# STM32WB05 register map
File version: 1.0
CPU: CM0+ r0p0, little endian, MPU, no FPU, 2 interrupt priority bits
Registers are 32-bit, read-write, reset 0x0 unless marked. A register's access mark holds for its fields unless they carry their own. Offsets are from the block's base; [hi:lo] are bit positions; {n}, {i} and the like mark numbered series; 'fields as' and 'values as' point back to an identical list.

## TIM16
Base 0x40005000
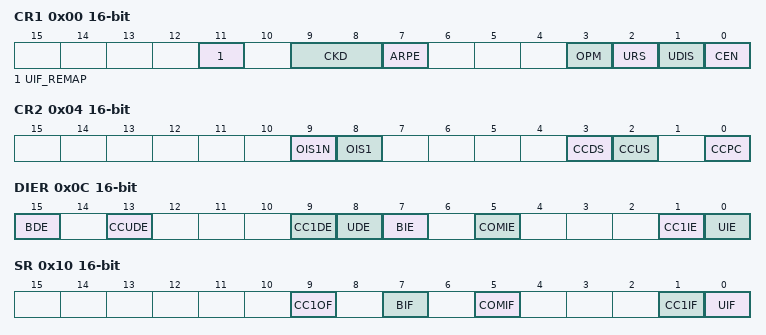
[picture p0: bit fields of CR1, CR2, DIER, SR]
0x00 CR1 16-bit
  [11] UIF_REMAP — UIFREMAP: UIF status bit remapping 0: No remapping. UIF status bit is not copied to TIMx_CNT register bit 31. 1: Remapping enabled. UIF status bit is copied to TIMx_CNT register bit 31.
  [9:8] CKD — CKD[1:0]: Clock division This bit-field indicates the division ratio between the timer clock (CK_INT) frequency and the dead-time and sampling clock (tDTS)used by the dead-time generators and the digital filters (TIx), 00: tDTS=tCK_INT 01: tDTS=2*tCK_INT 10: tDTS=4*tCK_INT 11: Reserved, do not program this value
    0=Div1 (t_DTS = t_CK_INT); 1=Div2 (t_DTS = 2 × t_CK_INT); 2=Div4 (t_DTS = 4 × t_CK_INT)
  [7] ARPE — ARPE: Auto-reload preload enable 0: TIMx_ARR register is not buffered 1: TIMx_ARR register is buffered
    0=Disabled (TIMx_APRR register is not buffered); 1=Enabled (TIMx_APRR register is buffered)
  [3] OPM — OPM: One pulse mode 0: Counter is not stopped at update event. 1: Counter stops counting at the next update event (clearing the bit CEN)
    0=Disabled (Counter is not stopped at update event); 1=Enabled (Counter stops counting at the next update event (clearing the CEN bit))
  [2] URS — URS: Update request source This bit is set and cleared by software to select the UEV event sources. 0: Any of the following events generate an update interrupt or DMA request if enabled. These events can be: - Counter overflow/underflow - Setting the UG bit - Update generation through the slave mode controller 1: Only counter overflow/underflow generates an update interrupt or DMA request if enabled.
    0=AnyEvent (Any of counter overflow/underflow, setting UG, or update through slave mode, generates an update interrupt or DMA request); 1=CounterOnly (Only counter overflow/underflow generates an update interrupt or DMA request)
  [1] UDIS — UDIS: Update disable This bit is set and cleared by software to enable/disable UEV event generation. 0: UEV enabled. The Update (UEV) event is generated by one of the following events: - Counter overflow/underflow - Setting the UG bit - Update generation through the slave mode controller Buffered registers are then loaded with their preload values. 1: UEV disabled. The Update event is not generated, shadow registers keep their value (ARR, PSC, CCRx). However the counter and the prescaler are reinitialized if the UG bit is set or if a hardware reset is received from the slave mode controller.
    0=Enabled (Update event enabled); 1=Disabled (Update event disabled)
  [0] CEN — CEN: Counter enable 0: Counter disabled 1: Counter enabled Note: External clock and gated mode can work only if the CEN bit has been previously set by software. However trigger mode can set the CEN bit automatically by hardware.
    0=Disabled (Counter disabled); 1=Enabled (Counter enabled)
0x04 CR2 16-bit
  [n+8] OIS{n}N (n=1..1) — Output Idle state (OC{n}N output)
    0=Reset (OCxN=0 after a dead-time when MOE=0); 1=Set (OCxN=1 after a dead-time when MOE=0)
  [n+7] OIS{n} (n=1..1) — Output Idle state (OC{n} output)
    0=Reset (OCx=0 (after a dead-time if OCx(N) is implemented) when MOE=0); 1=Set (OCx=1 (after a dead-time if OCx(N) is implemented) when MOE=0)
  [3] CCDS — CCDS: Capture/compare DMA selection 0: CCx DMA request sent when CCx event occurs 1: CCx DMA requests sent when update event occurs
    0=OnCompare (CCx DMA request sent when CCx event occurs); 1=OnUpdate (CCx DMA request sent when update event occurs)
  [2] CCUS — CCUS: Capture/compare control update selection 0: When capture/compare control bits are preloaded (CCPC=1), they are updated by setting the COMG bit only. 1: When capture/compare control bits are preloaded (CCPC=1), they are updated by setting the COMG bit or when an rising edge occurs on TRGI. Note: This bit acts only on channels that have a complementary output.
    0=Sw (When capture/compare control bits are preloaded (CCPC=1), they are updated by setting the COMG bit only); 1=SwOrEdge (When capture/compare control bits are preloaded (CCPC=1), they are updated by setting the COMG bit or when an rising edge occurs on TRGI)
  [0] CCPC — CCPC: Capture/compare preloaded control 0: CCxE, CCxNE and OCxM bits are not preloaded 1: CCxE, CCxNE and OCxM bits are preloaded, after having been written, they are updated only when COM bit is set. Note: This bit acts only on channels that have a complementary output.
    0=NotPreloaded (CCxE, CCxNE and OCxM bits are not preloaded); 1=Preloaded (CCxE, CCxNE and OCxM bits are preloaded)
0x0C DIER 16-bit
  [15] BDE — BDE: Break DMA request Enable. Not used in Blue51. Not available in IUM 0: Break DMA request disabled. 1: Break DMA request enabled.
  [9] CC{x}DE (x=1,U; step 4) — Capture/Compare {x} DMA request enable
    0=Disabled (CCx DMA request disabled); 1=Enabled (CCx DMA request enabled)
  [8] UDE — UDE: Update DMA request enable 0: Update DMA request disabled 1: Update DMA request enabled
    0=Disabled (Update DMA request disabled); 1=Enabled (Update DMA request enabled)
  [7] BIE — BIE: Break interrupt enable 0: Break interrupt disabled 1: Break interrupt enabled
    0=Disabled (Break interrupt disabled); 1=Enabled (Break interrupt enabled)
  [5] COMIE — COMIE: COM interrupt enable 0: COM interrupt disabled 1: COM interrupt enabled
    0=Disabled (COM interrupt disabled); 1=Enabled (COM interrupt enabled)
  [n] CC{n}IE (n=1..1) — Capture/Compare {n} interrupt enable
    0=Disabled (CCx interrupt disabled); 1=Enabled (CCx interrupt enabled)
  [0] UIE — UIE: Update interrupt enable 0: Update interrupt disabled 1: Update interrupt enabled
    0=Disabled (Update interrupt disabled); 1=Enabled (Update interrupt enabled)
0x10 SR 16-bit
  [n+8] CC{n}OF (n=1..1) write-0-clears — Capture/Compare {n} overcapture flag
    on read: 0=No overcapture has been detected; 1=Overcapture (The counter value has been captured in TIMx_CCRx register while CCxIF flag was already set) | on write: 0=Clear flag
  [7] BIF write-0-clears — BIF: Break interrupt flag This flag is set by hardware as soon as the break input goes active. It can be cleared by software if the break input is not active. 0: No break event occurred 1: An active level has been detected on the break input
    on read: 0=NoTrigger (No break event occurred); 1=Trigger (An active level has been detected on the break input. An interrupt is generated if BIE=1 in the TIMx_DIER register) | on write: 0=Clear flag
  [5] COMIF write-0-clears — COMIF: COM interrupt flag This flag is set by hardware on a COM event (once the capture/compare control bits CCxE, CCxNE, OCxMhave been updated). It is cleared by software. 0: No COM event occurred 1: COM interrupt pending
    on read: 0=No COM event occurred; 1=COM (COM interrupt pending) | on write: 0=Clear flag
  [n] CC{n}IF (n=1..1) write-0-clears — Capture/compare {n} interrupt flag
    on read: 0=NoMatch (No campture/compare has been detected); 1=Match (If CC1 is an output: The content of the counter TIMx_CNT matches the content of the TIMx_CCR1 register. If CC1 is an input: The counter value has been captured in TIMx_CCR1 register.) | on write: 0=Clear flag
  [0] UIF write-0-clears — UIF: Update interrupt flag This bit is set by hardware on an update event. It is cleared by software. 0: No update occurred. 1: Update interrupt pending. This bit is set by hardware when the registers are updated: At overflow regarding the repetition counter value (update if repetition counter = 0) and if the UDIS=0 in the TIMx_CR1 register. When CNT is reinitialized by software using the UG bit in TIMx_EGR register, if URS=0 and UDIS=0 in the TIMx_CR1 register.
    on read: 0=NoUpdateOccurred; 1=UpdatePending (Update interrupt pending) | on write: 0=Clear flag
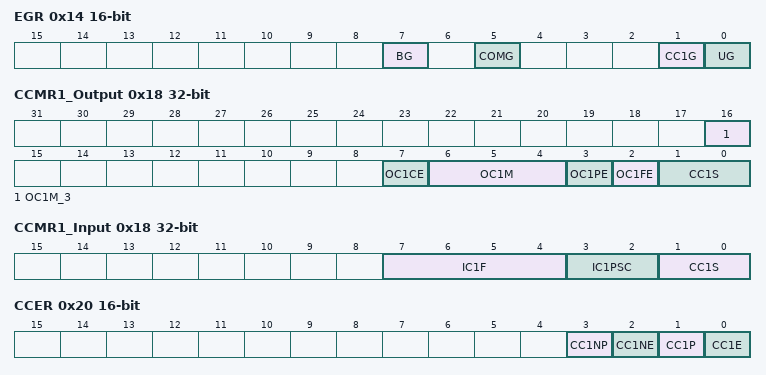
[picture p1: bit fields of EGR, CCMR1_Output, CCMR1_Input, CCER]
0x14 EGR 16-bit
  [7] BG wo — BG: Break generation This bit is set by software in order to generate an event, it is automatically cleared by hardware. 0: No action. 1: A break event is generated. MOE bit is cleared and BIF flag is set. Related interrupt or DMA transfer can occur if enabled.
    1=Trigger (A break event is generated. MOE bit is cleared and BIF flag is set. Related interrupt or DMA transfer can occur if enabled)
  [5] COMG wo — COMG: Capture/Compare control update generation This bit can be set by software, it is automatically cleared by hardware. 0: No action 1: When the CCPC bit is set, it is possible to update the CCxE, CCxNE and OCxM bits Note: This bit acts only on channels that have a complementary output.
    1=Trigger (When CCPC bit is set, it allows CCxE, CCxNE and OCxM bits to be updated)
  [n] CC{n}G (n=1..1) wo — Capture/compare {n} generation
    1=Trigger (If CC1 is an output: CC1IF flag is set, Corresponding interrupt or DMA request is sent if enabled. If CC1 is an input: The current value of the counter is captured in TIMx_CCR1 register.)
  [0] UG wo — UG: Update generation This bit can be set by software, it is automatically cleared by hardware. 0: No action. 1: Reinitialize the counter and generates an update of the registers. Note that the prescaler counter is cleared too (anyway the prescaler ratio is not affected).
    1=Update (Re-initializes the timer counter and generates an update of the registers.)
0x18 CCMR1_Output — CCMR1 register
  [n+15] OC{n}M_3 (n=1..1) — Output compare {n} mode, bit 3
  [n+6] OC{n}CE (n=1..1) — Output compare {n} clear enable
  [n+5:n+3] OC{n}M (n=1..1) — Output compare {n} mode
    0=Frozen (The comparison between the output compare register TIMx_CCRy and the counter TIMx_CNT has no effect on the outputs); 1=ActiveOnMatch (Set channel to active level on match. OCyREF signal is forced high when the counter matches the capture/compare register); 2=InactiveOnMatch (Set channel to inactive level on match. OCyREF signal is forced low when the counter matches the capture/compare register); 3=Toggle (OCyREF toggles when TIMx_CNT=TIMx_CCRy); 4=ForceInactive (OCyREF is forced low); 5=ForceActive (OCyREF is forced high); 6=PwmMode1 (In upcounting, channel is active as long as TIMx_CNT<TIMx_CCRy else inactive. In downcounting, channel is inactive as long as TIMx_CNT>TIMx_CCRy else active); 7=PwmMode2 (Inversely to PwmMode1)
  [n+2] OC{n}PE (n=1..1) — Output compare {n} preload enable
    0=Disabled (Preload register on CCRx disabled. New values written to CCRx are taken into account immediately); 1=Enabled (Preload register on CCRx enabled. Preload value is loaded into active register on each update event)
  [n+1] OC{n}FE (n=1..1) — Output compare {n} fast enable
    0=Disabled (Fast output disabled); 1=Enabled (Fast output enabled)
  [n:n-1] CC{n}S (n=1..1) — Capture/Compare {n} selection
    0=Output (CCx channel is configured as output)
0x18 CCMR1_Input (reset mask 0xF) (alternate view of CCMR1)
  [n+6:n+3] IC{n}F (n=1..1) — Input capture {n} filter
    0=No filter, sampling is done at fDTS; 1=FCK_INT_N2 (fSAMPLING=fCK_INT, N=2); 2=FCK_INT_N4 (fSAMPLING=fCK_INT, N=4); 3=FCK_INT_N8 (fSAMPLING=fCK_INT, N=8); 4=FDTS_Div2_N6 (fSAMPLING=fDTS/2, N=6); 5=FDTS_Div2_N8 (fSAMPLING=fDTS/2, N=8); 6=FDTS_Div4_N6 (fSAMPLING=fDTS/4, N=6); 7=FDTS_Div4_N8 (fSAMPLING=fDTS/4, N=8); 8=FDTS_Div8_N6 (fSAMPLING=fDTS/8, N=6); 9=FDTS_Div8_N8 (fSAMPLING=fDTS/8, N=8); 10=FDTS_Div16_N5 (fSAMPLING=fDTS/16, N=5); 11=FDTS_Div16_N6 (fSAMPLING=fDTS/16, N=6); 12=FDTS_Div16_N8 (fSAMPLING=fDTS/16, N=8); 13=FDTS_Div32_N5 (fSAMPLING=fDTS/32, N=5); 14=FDTS_Div32_N6 (fSAMPLING=fDTS/32, N=6); 15=FDTS_Div32_N8 (fSAMPLING=fDTS/32, N=8)
  [n+2:n+1] IC{n}PSC (n=1..1) — Input capture {n} prescaler
    0=No prescaler, capture is done each time an edge is detected on the capture input; 1=TwoEvents (Capture is done once every 2 events); 2=FourEvents (Capture is done once every 4 events); 3=EightEvents (Capture is done once every 8 events)
  [1:0] CC1S — CC1S: Capture/Compare 1 Selection This bit-field defines the direction of the channel (input/output) as well as the used input. 00: CC1 channel is configured as output 01: CC1 channel is configured as input, IC1 is mapped on TI1 1x: Reserved Note: CC1S bits are writable only when the channel is OFF (CC1E = '0' in TIMx_CCER).
    1=TI1 (CC1 channel is configured as input, IC1 is mapped on TI1)
0x20 CCER 16-bit
  [n+2] CC{n}NP (n=1..1) — Capture/Compare {n} output Polarity
    0=ActiveHigh (OCxN active high); 1=ActiveLow (OCxN active low)
  [n+1] CC{n}NE (n=1..1) — Capture/Compare {n} complementary output enable
    0=Disabled (Complementary output disabled); 1=Enabled (Complementary output enabled)
  [n] CC{n}P (n=1..1) — Capture/Compare {n} output Polarity
    0=RisingEdge (Noninverted/rising edge); 1=FallingEdge (Inverted/falling edge)
  [n-1] CC{n}E (n=1..1) — Capture/Compare {n} output enable
    0=Disabled (Capture disabled); 1=Enabled (Capture enabled)
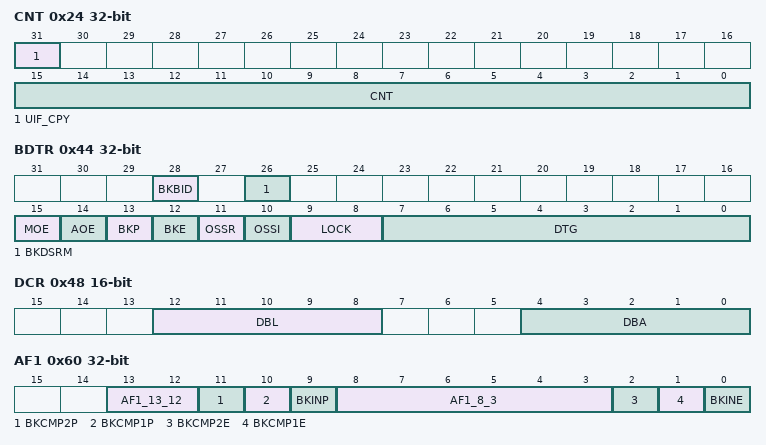
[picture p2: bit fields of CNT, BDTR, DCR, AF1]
0x24 CNT
  [31] UIF_CPY ro — UIFCPY: UIF Copy This bit is a read-only copy of the UIF bit of the TIMx_ISR register. If the UIFREMAP bit in TIMx_CR1 is reset, bit 31 is reserved and read as 0.
  [15:0] CNT — CNT[15:0]: Counter value
0x24 CNT16 16-bit (alternate view of CNT) — 16-bit counter register
  [15:0] CNT — counter value
0x28 PSC 16-bit
  [15:0] PSC — PSC[15:0]: Prescaler value The counter clock frequency (CK_CNT) is equal to fCK_PSC / (PSC[15:0] + 1). PSC contains the value to be loaded in the active prescaler register at each update event (including when the counter is cleared through UG bit of TIMx_EGR register or through trigger controller when configured in 'reset mode').
0x2C ARR 16-bit reset 0xFFFF
  [15:0] ARR — ARR[15:0]: Prescaler value ARR is the value to be loaded in the actual auto-reload register. Refer to the Section 22.3.1: Time-base unit on page 418 for more details about ARR update and behavior. The counter is blocked while the auto-reload value is null.
0x30 RCR 16-bit
  [7:0] REP — REP[7:0]: Repetition counter value These bits allow the user to set-up the update rate of the compare registers (i.e. periodic transfers from preload to active registers) when preload registers are enable, as well as the update interrupt generation rate, if this interrupt is enable. Each time the REP_CNT related downcounter reaches zero, an update event is generated and it restarts counting from REP value. As REP_CNT is reloaded with REP value only at the repetition update event U_RC, any write to the TIMx_RCR register is not taken in account until the next repetition update event. It means in PWM mode (REP+1) corresponds to the number of PWM periods in edge-aligned mode.
{0x32+2i} CCR{i} (i=1..1) 16-bit — capture/compare register
  [15:0] CCR — CCR1[15:0]: Capture/Compare 1 value If channel CC1 is configured as output: CCR1 is the value to be loaded in the actual capture/compare 1 register (preload value). It is loaded permanently if the preload feature is not selected in the TIMx_CCMR1 register (bit OC1PE). Else the preload value is copied in the active capture/compare 1 register when an update event occurs. The active capture/compare register contains the value to be compared to the counter TIMx_CNT and signaled on OC1 output. If channel CC1 is configured as input: CCR1 is the counter value transferred by the last input capture 1 event (IC1).
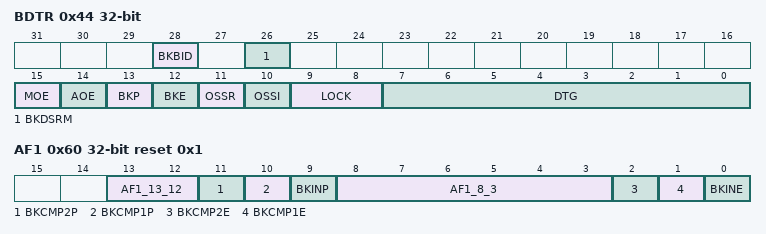
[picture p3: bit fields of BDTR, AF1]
0x44 BDTR
  [28] BKBID — BKBID: Break Bidirectional 0: Break input BRK in input mode 1: Break input BRK in bidirectional mode In the bidirectional mode (BKBID bit set to 1), the break input is configured both in input mode and in open drain output mode. Any active break event asserts a low logic level on the Break input to indicate an internal break event to external devices. Note: This bit cannot be modified as long as LOCK level 1 has been programmed (LOCK bits in TIMx_BDTR register). Note: Any write operation to this bit takes a delay of 1 APB clock cycle to become effective.
  [26] BKDSRM — BKDSRM: Break Disarm 0: Break input BRK is armed 1: Break input BRK is disarmed This bit is cleared by hardware when no break source is active. The BKDSRM bit must be set by software to release the bidirectional output control (opendrain output in Hi-Z state) and then be polled it until it is reset by hardware, indicating that the fault condition has disappeared. Note: Any write operation to this bit takes a delay of 1 APB clock cycle to become effective.
  [15] MOE — MOE: Main output enable This bit is cleared asynchronously by hardware as soon as the break input is active. It is set by software or automatically depending on the AOE bit. It is acting only on the channels which are configured in output. 0: OC and OCN outputs are disabled or forced to idle state depending on the OSSI bit. 1: OC and OCN outputs are enabled if their respective enable bits are set (CCxE, CCxNE in TIMx_CCER register) See OC/OCN enable description for more details (Section 22.4.8: TIM16 capture/compare enable register (TIMx_CCER)).
    0=DisabledIdle (OC/OCN are disabled or forced idle depending on OSSI); 1=Enabled (OC/OCN are enabled if CCxE/CCxNE are set)
  [14] AOE — AOE: Automatic output enable not be active) Note: This bit can not be modified as long as LOCK level 1 has been programmed (LOCK bits in TIMx_BDTR register).
    0=Manual (MOE can be set only by software); 1=Automatic (MOE can be set by software or automatically at the next update event (if none of the break inputs BRK and BRK2 is active))
  [13] BKP — BKP: Break polarity 0: Break input BRK is active low. 1: Break input BRK is active high Note: 1. This bit can not be modified as long as LOCK level 1 has been programmed (LOCK bits in TIMx_BDTR register). Note: 2. Any write operation to this bit takes a delay of 1 APB clock cycle to become effective.
    0=ActiveLow (Break input BRKx is active low); 1=ActiveHigh (Break input BRKx is active high)
  [12] BKE — BKE: Break enable 1; Break inputs (BRK) enabled Note: 1. This bit cannot be modified when LOCK level 1 has been programmed (LOCK bits in TIMx_BDTR register). Note: 2. Any write operation to this bit takes a delay of 1 APB clock cycle to become effective.
    0=Disabled (Break function x disabled); 1=Enabled (Break function x enabled)
  [11] OSSR — OSSR: Off-state selection for Run mode This bit is used when MOE=1 on channels that have a complementary output which are configured as outputs. OSSR is not implemented if no complementary output is implemented in the timer. See OC/OCN enable description for more details (Section 22.4.8: TIM16 capture/compare enable register (TIMx_CCER)). 0: When inactive, OC/OCN outputs are disabled (the timer releases the output control which is taken over by the AFIO logic, which forces a Hi-Z state) 1: When inactive, OC/OCN outputs are enabled with their inactive level as soon as CCxE=1 or CCxNE=1 (the output is still controlled by the timer). Note: This bit can not be modified as soon as the LOCK level 2 has been programmed (LOCK bits in TIMx_BDTR register).
    0=HiZ (When inactive, OC/OCN outputs are disabled); 1=IdleLevel (When inactive, OC/OCN outputs are enabled with their inactive level)
  [10] OSSI — OSSI: Off-state selection for Idle mode This bit is used when MOE=0 on channels configured as outputs. See OC/OCN enable description for more details (Section 22.4.8: TIM16 capture/compare enable register (TIMx_CCER)). 0: When inactive, OC/OCN outputs are disabled (OC/OCN enable output signal=0) 1: When inactive, OC/OCN outputs are forced first with their idle level as soon as CCxE=1 or CCxNE=1. OC/OCN enable output signal=1) Note: This bit can not be modified as soon as the LOCK level 2 has been programmed (LOCK bits in TIMx_BDTR register).
    0=HiZ (When inactive, OC/OCN outputs are disabled); 1=IdleLevel (When inactive, OC/OCN outputs are forced to idle level)
  [9:8] LOCK — LOCK[1:0]: Lock configuration These bits offer a write protection against software errors. 00: LOCK OFF - No bit is write protected 01: LOCK Level 1 = DTG bits in TIMx_BDTR register, OISx and OISxN bits in TIMx_CR2 register, BKE/BKP/AOE/BKBID/BKDSRM bits in TIMx_BDTR register and all used bits in TIMx_AF1 register can no longer be written. 10: LOCK Level 2 = LOCK Level 1 + CC Polarity bits (CCxP/CCxNP bits in TIMx_CCER register, as long as the related channel is configured in output through the CCxS bits) as well as OSSR and OSSI bits can no longer be written. 11: LOCK Level 3 = LOCK Level 2 + CC Control bits (OCxM and OCxPE bits in TIMx_CCMRx registers, as long as the related channel is configured in output through the CCxS bits) can no longer be written. Note: The LOCK bits can be written only once after the reset. Once the TIMx_BDTR register has been written, their content is frozen until the next reset.
    0=Off (No bit is write protected); 1=Level1 (Any bits except MOE, OSSR, OSSI and LOCK in TIMx_BDTR register, OISx and OISxN bits in TIMx_CR2 register can no longer be written); 2=Level2 (LOCK Level 1 + CC Polarity bits (CCxP/CCxNP bits in TIMx_CCER register, as long as the related channel is configured in output through the CCxS bits) as well as OSSR and OSSI bits can no longer be written); 3=Level3 (LOCK Level 2 + CC Control bits (OCxM and OCxPE bits in TIMx_CCMRx registers, as long as the related channel is configured in output through the CCxS bits) can no longer be written)
  [7:0] DTG — DTG[7:0]: Dead-time generator setup This bit-field defines the duration of the dead-time inserted between the complementary outputs. DT correspond to this duration. DTG[7:5]=0xx => DT=DTG[7:0]x tdtg with tdtg=tDTS DTG[7:5]=10x => DT=(64+DTG[5:0])xtdtg with Tdtg=2xtDTS DTG[7:5]=110 => DT=(32+DTG[4:0])xtdtg with Tdtg=8xtDTS DTG[7:5]=111 => DT=(32+DTG[4:0])xtdtg with Tdtg=16xtDTS Example if TDTS=125ns (8MHz), dead-time possible values are: 0 to 15875 ns by 125 ns steps, 16 us to 31750 ns by 250 ns steps, 32 us to 63 us by 1 us steps, 64 us to 126 us by 2 us steps Note: This bit-field can not be modified as long as LOCK level 1, 2 or 3 has been programmed (LOCK bits in TIMx_BDTR register).
0x48 DCR 16-bit
  [12:8] DBL — DBL[4:0]: DMA burst length This 5-bit field defines the length of DMA transfers (the timer recognizes a burst transfer when a read or a write access is done to the TIMx_DMAR address), i.e. the number of transfers. Transfers can be in half-words or in bytes (see example below). 00000: 1 transfer, 00001: 2 transfers, 00010: 3 transfers, ... 10001: 18 transfers.
  [4:0] DBA — DBA[4:0]: DMA base address This 5-bit field defines the base-address for DMA transfers (when read/write access are done through the TIMx_DMAR address). DBA is defined as an offset starting from the address of the TIMx_CR1 register. Example: 00000: TIMx_CR1, 00001: TIMx_CR2, 00010: Reserved, ... Example: Let us consider the following transfer: DBL = 7 transfers and DBA = TIMx_CR1. In this case the transfer is done to/from 7 registers starting from the TIMx_CR1 address.
0x4C DMAR 16-bit
  [15:0] DMAB — DMAB[15:0]: DMA register for burst accesses A read or write operation to the DMAR register accesses the register located at the address (TIMx_CR1 address) + (DBA + DMA index) x 4 where TIMx_CR1 address is the address of the control register 1, DBA is the DMA base address configured in TIMx_DCR register, DMA index is automatically controlled by the DMA transfer, and ranges from 0 to DBL (DBL configured in TIMx_DCR).
0x60 AF1
  [13:12] AF1_13_12 — AF1[13:12] Not used in Blue51. Not available in IUM
  [11] BKCMP2P — BKCMP2P: BRK COMP2 input polarity. This bit selects the COMP2 input sensitivity. It must be programmed together with the BKP polarity bit. 0: COMP2 input is active low. 1: COMP2 input is active high. Note: This bit can not be modified as long as LOCK level 1 has been programmed (LOCK bits in TIMx_BDTR register)
  [10] BKCMP1P — BKCMP1P: BRK COMP1 input polarity. This bit selects the COMP1 input sensitivity. It must be programmed together with the BKP polarity bit. 0: COMP1 input is active low. 1: COMP1 input is active high. Note: This bit can not be modified as long as LOCK level 1 has been programmed (LOCK bits in TIMx_BDTR register)
  [9] BKINP — BKINP: BRK BKIN input polarity. This bit selects the BKIN alternate function input sensitivity. It must be programmed together with the BKP polarity bit. 0: BKIN input is active low. 1: BKIN input is active high. Note: This bit can not be modified as long as LOCK level 1 has been programmed (LOCK bits in TIMx_BDTR register)
  [8:3] AF1_8_3 — AF1[13:12] Not used in Blue51. Not available in IUM
  [2] BKCMP2E — BKCMP1E: BRK COMP1 enable. This bit enables the COMP1 for the timer's BRK input. COMP1 output is ORed with the other enabled BRK sources. 0: COMP1 input disabled. 1: COMP1 input enabled. Note: This bit can not be modified as long as LOCK level 1 has been programmed (LOCK bits in TIMx_BDTR register)
  [1] BKCMP1E — BKCMP1E: BRK COMP1 enable. This bit enables the COMP1 for the timer's BRK input. COMP1 output is ORed with the other enabled BRK sources. 0: COMP1 input disabled. 1: COMP1 input enabled. Note: This bit can not be modified as long as LOCK level 1 has been programmed (LOCK bits in TIMx_BDTR register)
  [0] BKINE — BKINE: BRK BKIN enable. This bit enables the BKIN alternate function input for the timer's BRK input. BKIN input is ORed with the other enabled BRK sources. 0: BKIN input disabled. 1: BKIN input enabled. Note: This bit can not be modified as long as LOCK level 1 has been programmed (LOCK bits in TIMx_BDTR register)
0x68 TISEL
  [3:0] TI1SEL — selects TI1[0] to TI1[15] input

## TIM17
Base 0x40006000
Registers as TIM16, without TISEL; these are added or differ:
0x44 BDTR
  fields as TIM16.BDTR
0x50 OR1
  [1:0] TI1_RMP — TI1_RMP[1:0]: Timer 17 input 1 connection This bit is set and cleared by software. 00: TIM17 TI1 is connected to GPIO 01: TIM17 TI1 is connected to LCO 1x: TIM17 TI1 is connected to MCO
0x60 AF1 reset 0x1 (reset mask 0xF)
  fields as TIM16.AF1
